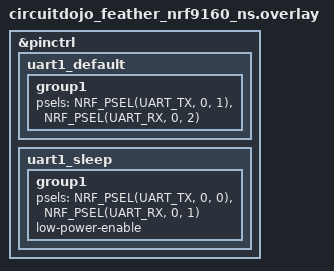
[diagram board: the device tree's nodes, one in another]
&pinctrl {
    /* configuration for uart0 device, default state */
    uart1_default: uart1_default {
		group1 {
			psels = <NRF_PSEL(UART_TX, 0, 1)>,
				    <NRF_PSEL(UART_RX, 0, 2)>;
		};
	};

	uart1_sleep: uart1_sleep {
		group1 {
			psels = <NRF_PSEL(UART_TX, 0, 0)>,
				    <NRF_PSEL(UART_RX, 0, 1)>;
			low-power-enable;
		};
	};
  };
